# COMPUTE_CLUSTER_PBIST_0_COMPUTE_CLUSTER_PBIST_0_K3_PBIST_4C28P_4BIT_WRAP_00330000h register map
Vendor: Texas Instruments
Peripheral module from a debugger description file (folder am62L).
Registers are 32-bit, read-write, reset 0x0 unless marked. A register's access mark holds for its fields unless they carry their own. Offsets are as the file gives them; lines under a group give offsets from that group; [hi:lo] are bit positions; {n}, {i} and the like mark numbered series; 'fields as' and 'values as' point back to an identical list; <NAME> marks a mode.

## COMPUTE_CLUSTER_PBIST_0_K3_PBIST_4C28P_4BIT_WRAP
{0x0+4i} COMPUTE_CLUSTER_PBIST_0_K3_PBIST_4C28P_4BIT_WRAP_RF{i}L (i=0..15)
  [31:0] RF{i}L — Register Files / Instruction Registers RF{i} lower (RF{i}L) Reset Source: mod_g_rst_n
{0x40+4i} COMPUTE_CLUSTER_PBIST_0_K3_PBIST_4C28P_4BIT_WRAP_RF{i}U (i=0..15)
  [31:0] RF{i}U — Register Files / Instruction Registers RF{i} upper (RF{i}U) Reset Source: mod_g_rst_n
{0x100+4i} COMPUTE_CLUSTER_PBIST_0_K3_PBIST_4C28P_4BIT_WRAP_A{i} (i=0..3)
  [15:0] A{i} — Variable Address Register {i} (A{i}) Reset Source: mod_g_rst_n
{0x110+4i} COMPUTE_CLUSTER_PBIST_0_K3_PBIST_4C28P_4BIT_WRAP_L{i} (i=0..3)
  [15:0] L{i} — Variable Loop Count Register {i} (L{i}) Reset Source: mod_g_rst_n
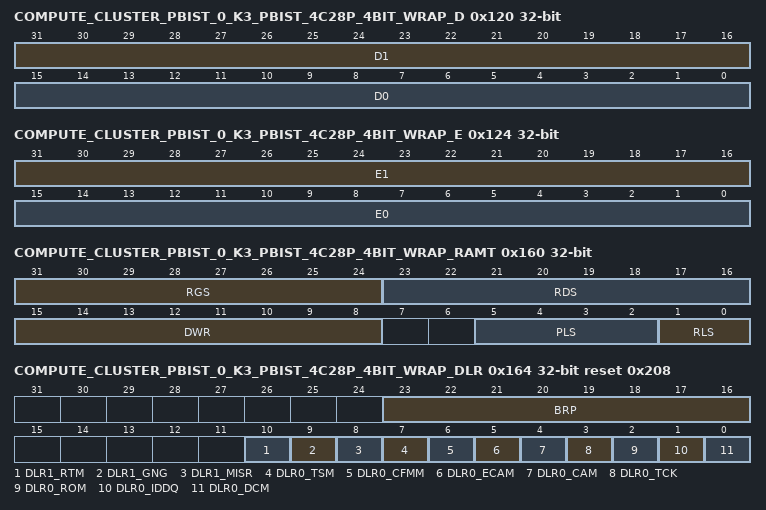
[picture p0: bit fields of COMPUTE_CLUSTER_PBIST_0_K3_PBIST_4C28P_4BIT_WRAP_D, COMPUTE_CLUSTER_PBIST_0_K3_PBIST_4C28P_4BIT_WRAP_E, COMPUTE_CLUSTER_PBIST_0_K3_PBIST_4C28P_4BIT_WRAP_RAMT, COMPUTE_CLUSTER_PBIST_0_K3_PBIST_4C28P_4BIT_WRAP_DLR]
0x120 COMPUTE_CLUSTER_PBIST_0_K3_PBIST_4C28P_4BIT_WRAP_D
  [31:16] D1 — DD1 Data Register Upper 16 (D1) Reset Source: mod_g_rst_n
  [15:0] D0 — DD0 Data Register Lower 16 (D0) Reset Source: mod_g_rst_n
0x124 COMPUTE_CLUSTER_PBIST_0_K3_PBIST_4C28P_4BIT_WRAP_E
  [31:16] E1 — EE1 Data Register Upper 16 (E1) Reset Source: mod_g_rst_n
  [15:0] E0 — EE0 Data Register Lower 16 (E0) Reset Source: mod_g_rst_n
{0x130+4i} COMPUTE_CLUSTER_PBIST_0_K3_PBIST_4C28P_4BIT_WRAP_CA{i} (i=0..3)
  [15:0] CA{i} — Constant Address Register {i} (CA{i}) Reset Source: mod_g_rst_n
{0x140+4i} COMPUTE_CLUSTER_PBIST_0_K3_PBIST_4C28P_4BIT_WRAP_CL{i} (i=0..3)
  [15:0] CL{i} — Constant Loop Count Register {i} (CL{i}) Reset Source: mod_g_rst_n
{0x150+4i} COMPUTE_CLUSTER_PBIST_0_K3_PBIST_4C28P_4BIT_WRAP_I{i} (i=0..3)
  [15:0] I0 — Constant Increment Register {i} (I{i}) Reset Source: mod_g_rst_n
0x160 COMPUTE_CLUSTER_PBIST_0_K3_PBIST_4C28P_4BIT_WRAP_RAMT
  [31:24] RGS — RAM Group Select RGS Reset Source: mod_g_rst_n
  [23:16] RDS — Return Data select RDS Reset Source: mod_g_rst_n
  [15:8] DWR — Data Width Register DWR Reset Source: mod_g_rst_n
  [5:2] PLS — Pipeline Latency Select Reset Source: mod_g_rst_n
  [1:0] RLS — RAM Latency Select Reset Source: mod_g_rst_n
0x164 COMPUTE_CLUSTER_PBIST_0_K3_PBIST_4C28P_4BIT_WRAP_DLR reset 0x208
  [23:16] BRP — Datalogger 2 (BRP) Reset Source: mod_g_rst_n
  [10] DLR1_RTM — Retention testing mode Reset Source: mod_g_rst_n
  [9] DLR1_GNG — GO / NO-GO testing mode Reset Source: mod_g_rst_n
  [8] DLR1_MISR — MISR testing mode (mainly for ROM testing) Reset Source: mod_g_rst_n
  [7] DLR0_TSM — Time stamp mode Reset Source: mod_g_rst_n
  [6] DLR0_CFMM — Column Fail Masking mode Reset Source: mod_g_rst_n
  [5] DLR0_ECAM — Emulation cache access mode Reset Source: mod_g_rst_n
  [4] DLR0_CAM — Config access mode Reset Source: mod_g_rst_n
  [3] DLR0_TCK — TCK Gated mode Reset Source: mod_g_rst_n
  [2] DLR0_ROM — ROM-based testing mode Reset Source: mod_g_rst_n
  [1] DLR0_IDDQ — IDDQ testing mode Reset Source: mod_g_rst_n
  [0] DLR0_DCM — Distributed Compare mode Reset Source: mod_g_rst_n
0x168 COMPUTE_CLUSTER_PBIST_0_K3_PBIST_4C28P_4BIT_WRAP_CMS
  [3:0] CMS — Clock Mux Select (CMS) Reset Source: mod_g_rst_n
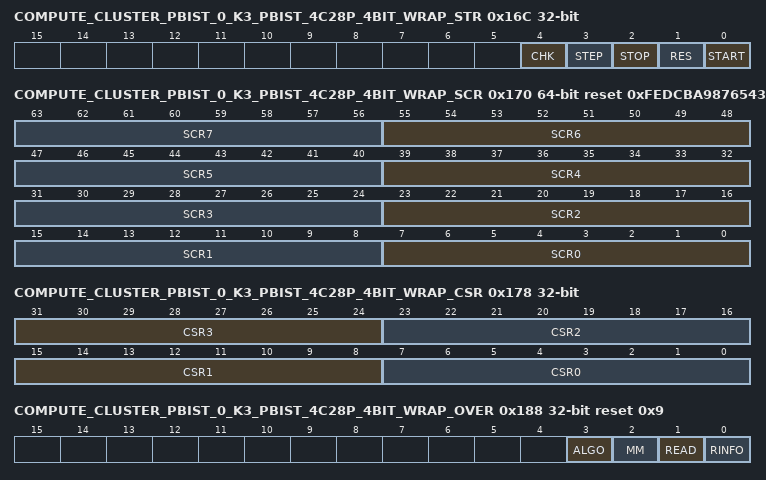
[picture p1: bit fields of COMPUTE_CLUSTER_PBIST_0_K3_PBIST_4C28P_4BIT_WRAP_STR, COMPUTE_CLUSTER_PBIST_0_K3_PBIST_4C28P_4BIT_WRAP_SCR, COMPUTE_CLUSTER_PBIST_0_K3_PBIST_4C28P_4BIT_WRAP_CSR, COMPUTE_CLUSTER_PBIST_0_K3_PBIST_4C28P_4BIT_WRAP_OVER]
0x16C COMPUTE_CLUSTER_PBIST_0_K3_PBIST_4C28P_4BIT_WRAP_STR
  [4] CHK — Check MISR mode Reset Source: mod_g_rst_n
  [3] STEP — Step / Step for emulation mode Reset Source: mod_g_rst_n
  [2] STOP — Stop Reset Source: mod_g_rst_n
  [1] RES — Resume / Emulation read Reset Source: mod_g_rst_n
  [0] START — Start / Time Stamp mode restart Reset Source: mod_g_rst_n
0x170 COMPUTE_CLUSTER_PBIST_0_K3_PBIST_4C28P_4BIT_WRAP_SCR 64-bit reset 0xFEDCBA9876543210
  [8n+7:8n] SCR{n} (n=0..7) — Address Scrambling Register {n} Reset Source: mod_g_rst_n
0x178 COMPUTE_CLUSTER_PBIST_0_K3_PBIST_4C28P_4BIT_WRAP_CSR
  [31:24] CSR3 — Chip Select 3 (CSR3) Reset Source: mod_g_rst_n
  [23:16] CSR2 — Chip Select 2 (CSR2) Reset Source: mod_g_rst_n
  [15:8] CSR1 — Chip Select 1(CSR1) Reset Source: mod_g_rst_n
  [7:0] CSR0 — Chip Select 0 (CSR0) Reset Source: mod_g_rst_n
0x17C COMPUTE_CLUSTER_PBIST_0_K3_PBIST_4C28P_4BIT_WRAP_FDLY reset 0x68
  [7:0] FDLY — Fail Delay (FDLY) Reset Source: mod_g_rst_n
0x180 COMPUTE_CLUSTER_PBIST_0_K3_PBIST_4C28P_4BIT_WRAP_PACT
  [0] PACT — PBIST Activate (PACT) Reset Source: mod_g_rst_n
0x184 COMPUTE_CLUSTER_PBIST_0_K3_PBIST_4C28P_4BIT_WRAP_PID
  [4:0] PID — PBIST ID Reset Source: mod_g_rst_n
0x188 COMPUTE_CLUSTER_PBIST_0_K3_PBIST_4C28P_4BIT_WRAP_OVER reset 0x9
  [3] ALGO — PBIST Override Algorithm Override Reset Source: mod_g_rst_n
  [2] MM — PBIST Override Multiple Memory Reset Source: mod_g_rst_n
  [1] READ — PBIST Override READ Override Reset Source: mod_g_rst_n
  [0] RINFO — PBIST Override RINFO Override Reset Source: mod_g_rst_n
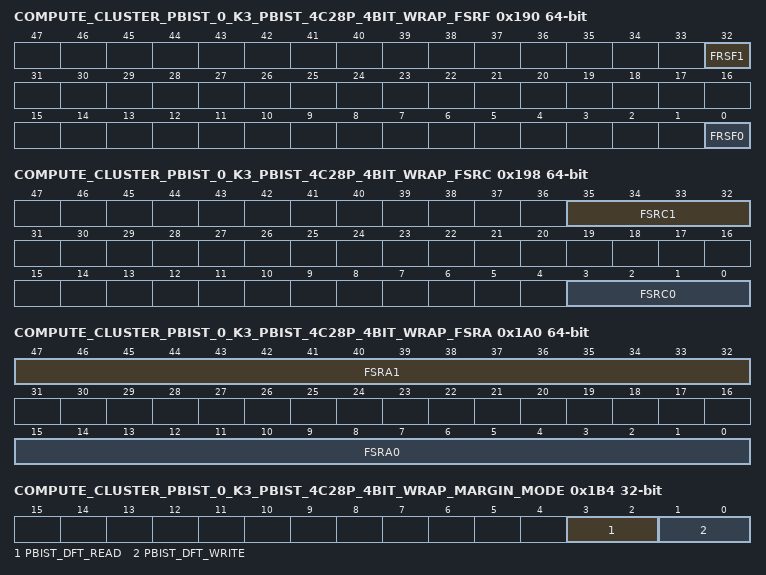
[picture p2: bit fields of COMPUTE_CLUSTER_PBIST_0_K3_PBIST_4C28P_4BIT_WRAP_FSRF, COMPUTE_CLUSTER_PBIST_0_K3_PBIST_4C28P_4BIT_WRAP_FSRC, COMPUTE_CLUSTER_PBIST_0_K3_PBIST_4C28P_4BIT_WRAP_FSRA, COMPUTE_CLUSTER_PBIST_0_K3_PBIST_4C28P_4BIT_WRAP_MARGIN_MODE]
0x190 COMPUTE_CLUSTER_PBIST_0_K3_PBIST_4C28P_4BIT_WRAP_FSRF 64-bit ro
  [32] FRSF1 — Fail Status Fail - Port 1 (FSRF1) Reset Source: mod_g_rst_n
  [0] FRSF0 — Fail Status Fail - Port 0 (FSRF0) Reset Source: mod_g_rst_n
0x198 COMPUTE_CLUSTER_PBIST_0_K3_PBIST_4C28P_4BIT_WRAP_FSRC 64-bit ro
  [35:32] FSRC1 — Fail Status Count - Port 1 (FSRC1) Reset Source: mod_g_rst_n
  [3:0] FSRC0 — Fail Status Count - Port 0 (FSRC0) Reset Source: mod_g_rst_n
0x1A0 COMPUTE_CLUSTER_PBIST_0_K3_PBIST_4C28P_4BIT_WRAP_FSRA 64-bit ro
  [47:32] FSRA1 — Fail Status Address - Port 1 (FSRA1) Reset Source: mod_g_rst_n
  [15:0] FSRA0 — Fail Status Address - Port 0 (FSRA0) Reset Source: mod_g_rst_n
0x1A8 COMPUTE_CLUSTER_PBIST_0_K3_PBIST_4C28P_4BIT_WRAP_FSRDL0 ro
  [31:0] FSRDL0 — Fail Status Data - Port 0 (FSRDL0) Reset Source: mod_g_rst_n
0x1B0 COMPUTE_CLUSTER_PBIST_0_K3_PBIST_4C28P_4BIT_WRAP_FSRDL1 ro
  [31:0] FSRDL1 — Fail Status Data - Port 1 (FSRDL1) Reset Source: mod_g_rst_n
0x1B4 COMPUTE_CLUSTER_PBIST_0_K3_PBIST_4C28P_4BIT_WRAP_MARGIN_MODE ro
  [3:2] PBIST_DFT_READ — pbist_dft_read[1:0] Reset Source: mod_g_rst_n
  [1:0] PBIST_DFT_WRITE — pbist_dft_write[1:0] Reset Source: mod_g_rst_n
0x1B8 COMPUTE_CLUSTER_PBIST_0_K3_PBIST_4C28P_4BIT_WRAP_WRENZ ro
  [1:0] WRENZ — pbist_ram_wrenz[1:0] Reset Source: mod_g_rst_n
0x1BC COMPUTE_CLUSTER_PBIST_0_K3_PBIST_4C28P_4BIT_WRAP_PAGE_PGS ro
  [1:0] PGS — pbist_ram_pgs[1:0] Reset Source: mod_g_rst_n
0x1C0 COMPUTE_CLUSTER_PBIST_0_K3_PBIST_4C28P_4BIT_WRAP_ROM reset 0x3
  [1:0] ROM — ROM Mask (ROM) Reset Source: mod_g_rst_n
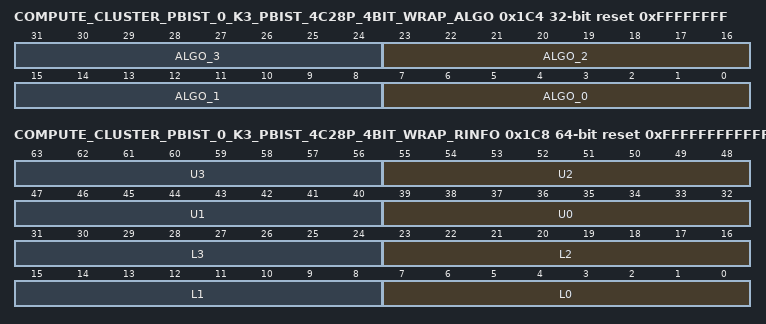
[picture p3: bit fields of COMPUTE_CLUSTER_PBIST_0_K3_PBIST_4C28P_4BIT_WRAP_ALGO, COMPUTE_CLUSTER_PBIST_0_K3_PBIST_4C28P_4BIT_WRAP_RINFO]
0x1C4 COMPUTE_CLUSTER_PBIST_0_K3_PBIST_4C28P_4BIT_WRAP_ALGO reset 0xFFFFFFFF
  [8n+7:8n] ALGO_{n} (n=0..3) — ROM Algorithm Mask {n} (ALGO {n}) Reset Source: mod_g_rst_n
0x1C8 COMPUTE_CLUSTER_PBIST_0_K3_PBIST_4C28P_4BIT_WRAP_RINFO 64-bit reset 0xFFFFFFFFFFFFFFFF
  [8n+39:8n+32] U{n} (n=0..3) — RAM Info Mask Upper {n} (RINFOU{n}) Reset Source: mod_g_rst_n
  [8n+7:8n] L{n} (n=0..3) — RAM Info Mask Lower {n} (RINFOL{n}) Reset Source: mod_g_rst_n
